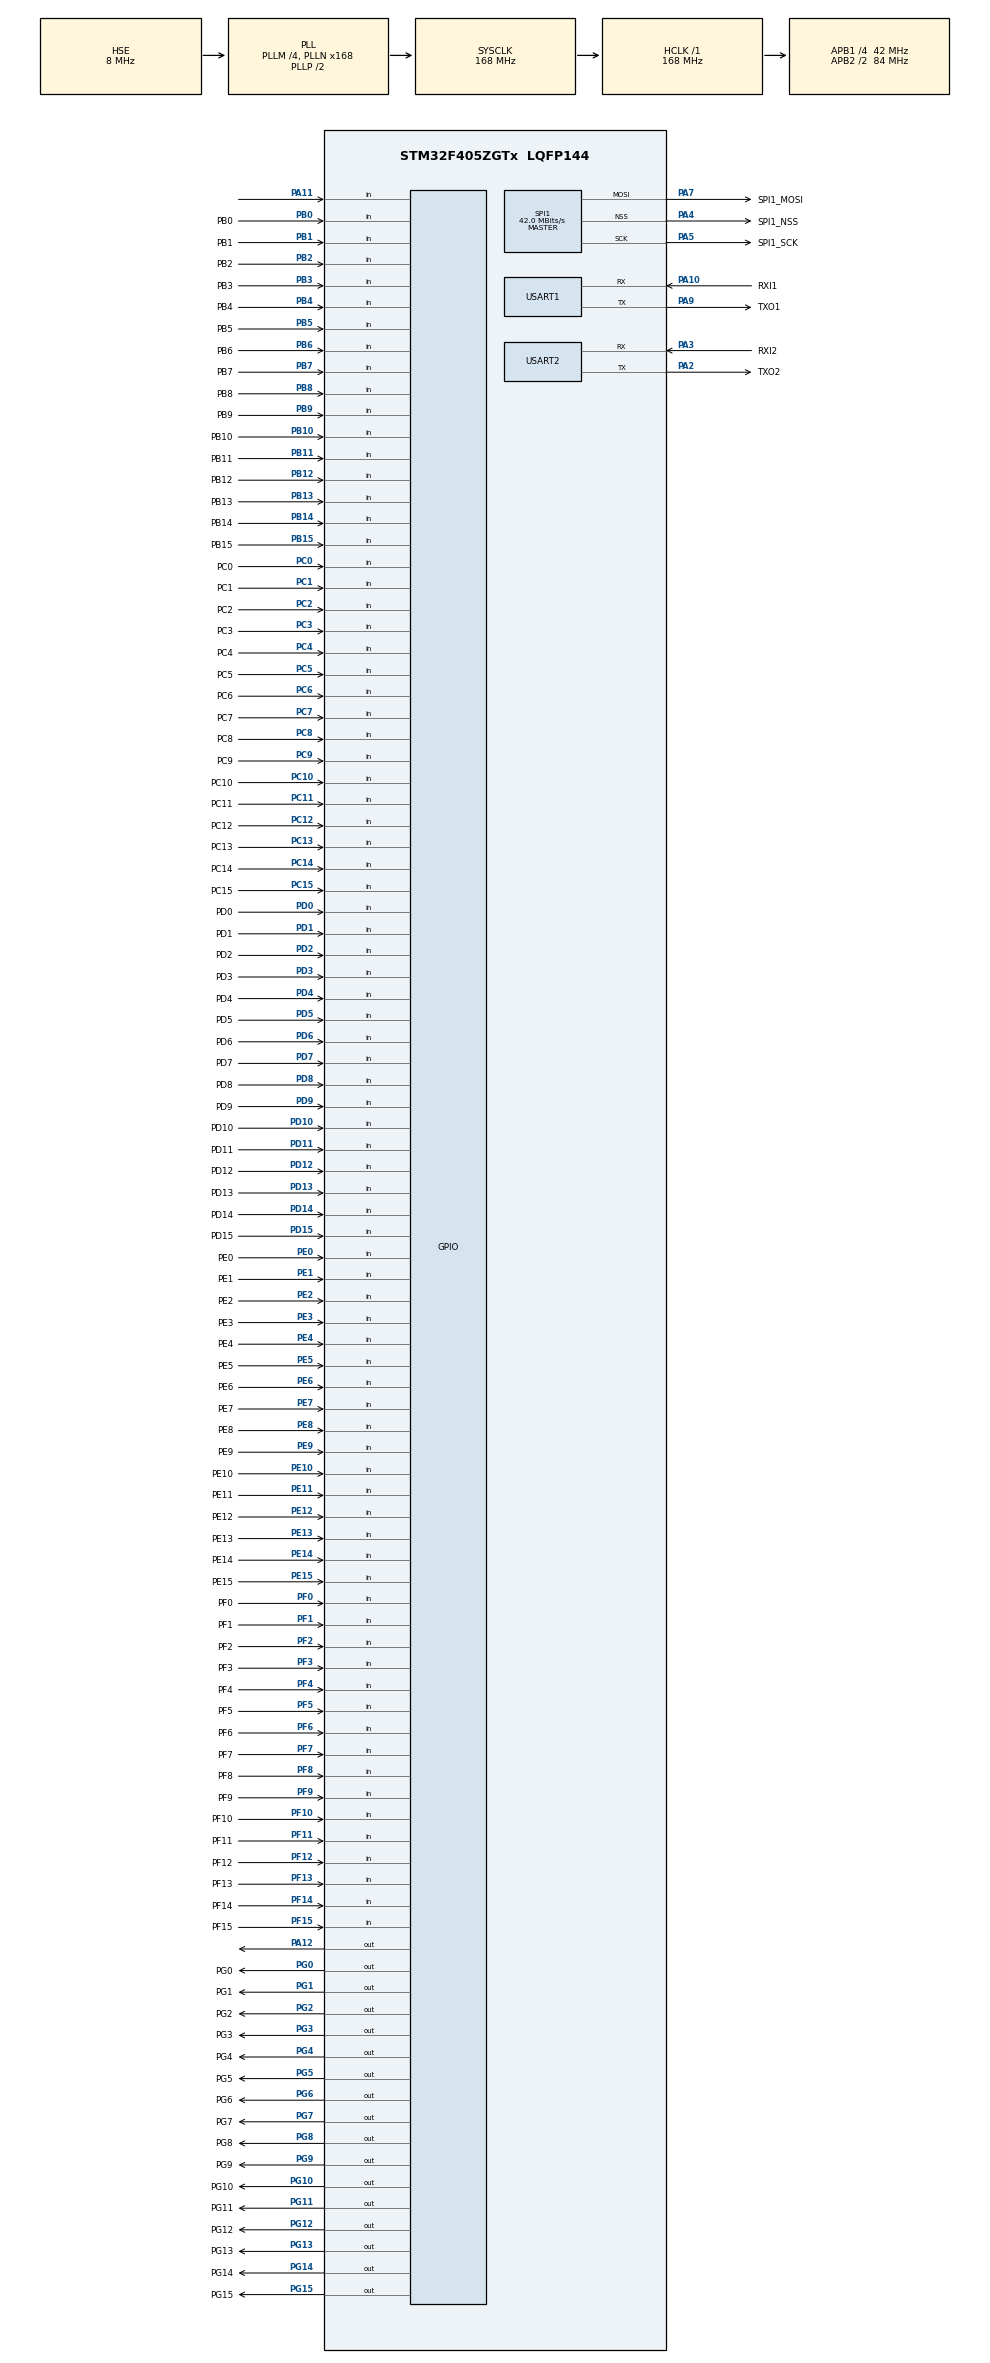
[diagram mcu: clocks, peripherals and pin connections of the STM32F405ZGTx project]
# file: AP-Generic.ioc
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Mcu.Family=STM32F4
Mcu.Name=STM32F405ZGTx
Mcu.Package=LQFP144
NVIC.PriorityGroup=NVIC_PRIORITYGROUP_4
NVIC.USART1_IRQn=true\:0\:0\:false\:false\:true\:true\:true\:true
PA10.GPIO_Label=RXI1
PA10.GPIO_PuPd=GPIO_PULLUP
PA10.Mode=Asynchronous
PA10.Signal=USART1_RX
PA11.GPIO_PuPd=GPIO_PULLUP
PA11.Signal=GPIO_Input
PA12.Signal=GPIO_Output
PA2.GPIO_Label=TXO2
PA2.Mode=Asynchronous
PA2.Signal=USART2_TX
PA3.GPIO_Label=RXI2
PA3.GPIO_PuPd=GPIO_PULLUP
PA3.Mode=Asynchronous
PA3.Signal=USART2_RX
PA4.GPIO_Label=SPI1_NSS
PA4.GPIO_PuPd=GPIO_PULLUP
PA4.Mode=NSS_Signal_Hard_Output
PA4.Signal=SPI1_NSS
PA5.GPIO_Label=SPI1_SCK
PA5.Mode=TX_Only_Simplex_Unidirect_Master
PA5.Signal=SPI1_SCK
PA6.GPIO_Label=SPI1_MIS0
PA6.GPIO_PuPd=GPIO_PULLDOWN
PA6.Signal=SPI1_MISO
PA7.GPIO_Label=SPI1_MOSI
PA7.Mode=TX_Only_Simplex_Unidirect_Master
PA7.Signal=SPI1_MOSI
PA9.GPIO_Label=TXO1
PA9.Mode=Asynchronous
PA9.Signal=USART1_TX
PB0.GPIO_Label=PB0
PB0.GPIO_PuPd=GPIO_PULLDOWN
PB0.Signal=GPIO_Input
PB1.GPIO_Label=PB1
PB1.GPIO_PuPd=GPIO_PULLDOWN
PB1.Signal=GPIO_Input
PB10.GPIO_Label=PB10
PB10.GPIO_PuPd=GPIO_PULLDOWN
PB10.Signal=GPIO_Input
PB11.GPIO_Label=PB11
PB11.GPIO_PuPd=GPIO_PULLDOWN
PB11.Signal=GPIO_Input
PB12.GPIO_Label=PB12
PB12.GPIO_PuPd=GPIO_PULLDOWN
PB12.Signal=GPIO_Input
PB13.GPIO_Label=PB13
PB13.GPIO_PuPd=GPIO_PULLDOWN
PB13.Signal=GPIO_Input
PB14.GPIO_Label=PB14
PB14.GPIO_PuPd=GPIO_PULLDOWN
PB14.Signal=GPIO_Input
PB15.GPIO_Label=PB15
PB15.GPIO_PuPd=GPIO_PULLDOWN
PB15.Signal=GPIO_Input
PB2.GPIO_Label=PB2
PB2.GPIO_PuPd=GPIO_PULLDOWN
PB2.Signal=GPIO_Input
PB3.GPIO_Label=PB3
PB3.GPIO_PuPd=GPIO_PULLDOWN
PB3.Signal=GPIO_Input
PB4.GPIO_Label=PB4
PB4.GPIO_PuPd=GPIO_PULLDOWN
PB4.Signal=GPIO_Input
PB5.GPIO_Label=PB5
PB5.GPIO_PuPd=GPIO_PULLDOWN
PB5.Signal=GPIO_Input
PB6.GPIO_Label=PB6
PB6.GPIO_PuPd=GPIO_PULLDOWN
PB6.Signal=GPIO_Input
PB7.GPIO_Label=PB7
PB7.GPIO_PuPd=GPIO_PULLDOWN
PB7.Signal=GPIO_Input
PB8.GPIO_Label=PB8
PB8.GPIO_PuPd=GPIO_PULLDOWN
PB8.Signal=GPIO_Input
PB9.GPIO_Label=PB9
PB9.GPIO_PuPd=GPIO_PULLDOWN
PB9.Signal=GPIO_Input
PC0.GPIO_Label=PC0
PC0.GPIO_PuPd=GPIO_PULLDOWN
PC0.Signal=GPIO_Input
PC1.GPIO_Label=PC1
PC1.GPIO_PuPd=GPIO_PULLDOWN
PC1.Signal=GPIO_Input
PC10.GPIO_Label=PC10
PC10.GPIO_PuPd=GPIO_PULLDOWN
PC10.Signal=GPIO_Input
PC11.GPIO_Label=PC11
PC11.GPIO_PuPd=GPIO_PULLDOWN
PC11.Signal=GPIO_Input
PC12.GPIO_Label=PC12
PC12.GPIO_PuPd=GPIO_PULLDOWN
PC12.Signal=GPIO_Input
PC13-ANTI_TAMP.GPIO_Label=PC13
PC13-ANTI_TAMP.GPIO_PuPd=GPIO_PULLDOWN
PC13-ANTI_TAMP.Signal=GPIO_Input
PC14-OSC32_IN.GPIO_Label=PC14
PC14-OSC32_IN.GPIO_PuPd=GPIO_PULLDOWN
PC14-OSC32_IN.Signal=GPIO_Input
PC15-OSC32_OUT.GPIO_Label=PC15
PC15-OSC32_OUT.GPIO_PuPd=GPIO_PULLDOWN
PC15-OSC32_OUT.Signal=GPIO_Input
PC2.GPIO_Label=PC2
PC2.GPIO_PuPd=GPIO_PULLDOWN
PC2.Signal=GPIO_Input
PC3.GPIO_Label=PC3
PC3.GPIO_PuPd=GPIO_PULLDOWN
PC3.Signal=GPIO_Input
PC4.GPIO_Label=PC4
PC4.GPIO_PuPd=GPIO_PULLDOWN
PC4.Signal=GPIO_Input
PC5.GPIO_Label=PC5
PC5.GPIO_PuPd=GPIO_PULLDOWN
PC5.Signal=GPIO_Input
PC6.GPIO_Label=PC6
PC6.GPIO_PuPd=GPIO_PULLDOWN
PC6.Signal=GPIO_Input
PC7.GPIO_Label=PC7
PC7.GPIO_PuPd=GPIO_PULLDOWN
PC7.Signal=GPIO_Input
PC8.GPIO_Label=PC8
PC8.GPIO_PuPd=GPIO_PULLDOWN
PC8.Signal=GPIO_Input
PC9.GPIO_Label=PC9
PC9.GPIO_PuPd=GPIO_PULLDOWN
PC9.Signal=GPIO_Input
PD0.GPIO_Label=PD0
PD0.GPIO_PuPd=GPIO_PULLDOWN
PD0.Signal=GPIO_Input
PD1.GPIO_Label=PD1
PD1.GPIO_PuPd=GPIO_PULLDOWN
PD1.Signal=GPIO_Input
PD10.GPIO_Label=PD10
PD10.GPIO_PuPd=GPIO_PULLDOWN
PD10.Signal=GPIO_Input
PD11.GPIO_Label=PD11
PD11.GPIO_PuPd=GPIO_PULLDOWN
PD11.Signal=GPIO_Input
PD12.GPIO_Label=PD12
PD12.GPIO_PuPd=GPIO_PULLDOWN
PD12.Signal=GPIO_Input
PD13.GPIO_Label=PD13
PD13.GPIO_PuPd=GPIO_PULLDOWN
PD13.Signal=GPIO_Input
PD14.GPIO_Label=PD14
PD14.GPIO_PuPd=GPIO_PULLDOWN
PD14.Signal=GPIO_Input
PD15.GPIO_Label=PD15
PD15.GPIO_PuPd=GPIO_PULLDOWN
PD15.Signal=GPIO_Input
PD2.GPIO_Label=PD2
PD2.GPIO_PuPd=GPIO_PULLDOWN
PD2.Signal=GPIO_Input
PD3.GPIO_Label=PD3
PD3.GPIO_PuPd=GPIO_PULLDOWN
PD3.Signal=GPIO_Input
PD4.GPIO_Label=PD4
PD4.GPIO_PuPd=GPIO_PULLDOWN
PD4.Signal=GPIO_Input
PD5.GPIO_Label=PD5
PD5.GPIO_PuPd=GPIO_PULLDOWN
PD5.Signal=GPIO_Input
PD6.GPIO_Label=PD6
PD6.GPIO_PuPd=GPIO_PULLDOWN
PD6.Signal=GPIO_Input
PD7.GPIO_Label=PD7
PD7.GPIO_PuPd=GPIO_PULLDOWN
PD7.Signal=GPIO_Input
PD8.GPIO_Label=PD8
PD8.GPIO_PuPd=GPIO_PULLDOWN
PD8.Signal=GPIO_Input
PD9.GPIO_Label=PD9
PD9.GPIO_PuPd=GPIO_PULLDOWN
PD9.Signal=GPIO_Input
PE0.GPIO_Label=PE0
PE0.GPIO_PuPd=GPIO_PULLDOWN
PE0.Signal=GPIO_Input
PE1.GPIO_Label=PE1
PE1.GPIO_PuPd=GPIO_PULLDOWN
PE1.Signal=GPIO_Input
PE10.GPIO_Label=PE10
PE10.GPIO_PuPd=GPIO_PULLDOWN
PE10.Signal=GPIO_Input
PE11.GPIO_Label=PE11
PE11.GPIO_PuPd=GPIO_PULLDOWN
PE11.Signal=GPIO_Input
PE12.GPIO_Label=PE12
PE12.GPIO_PuPd=GPIO_PULLDOWN
PE12.Signal=GPIO_Input
PE13.GPIO_Label=PE13
PE13.GPIO_PuPd=GPIO_PULLDOWN
PE13.Signal=GPIO_Input
PE14.GPIO_Label=PE14
PE14.GPIO_PuPd=GPIO_PULLDOWN
PE14.Signal=GPIO_Input
PE15.GPIO_Label=PE15
PE15.GPIO_PuPd=GPIO_PULLDOWN
PE15.Signal=GPIO_Input
PE2.GPIO_Label=PE2
PE2.GPIO_PuPd=GPIO_PULLDOWN
PE2.Signal=GPIO_Input
PE3.GPIO_Label=PE3
PE3.GPIO_PuPd=GPIO_PULLDOWN
PE3.Signal=GPIO_Input
PE4.GPIO_Label=PE4
PE4.GPIO_PuPd=GPIO_PULLDOWN
PE4.Signal=GPIO_Input
PE5.GPIO_Label=PE5
PE5.GPIO_PuPd=GPIO_PULLDOWN
PE5.Signal=GPIO_Input
PE6.GPIO_Label=PE6
PE6.GPIO_PuPd=GPIO_PULLDOWN
PE6.Signal=GPIO_Input
PE7.GPIO_Label=PE7
PE7.GPIO_PuPd=GPIO_PULLDOWN
PE7.Signal=GPIO_Input
PE8.GPIO_Label=PE8
PE8.GPIO_PuPd=GPIO_PULLDOWN
PE8.Signal=GPIO_Input
PE9.GPIO_Label=PE9
PE9.GPIO_PuPd=GPIO_PULLDOWN
PE9.Signal=GPIO_Input
PF0.GPIO_Label=PF0
PF0.GPIO_PuPd=GPIO_PULLDOWN
PF0.Signal=GPIO_Input
PF1.GPIO_Label=PF1
PF1.GPIO_PuPd=GPIO_PULLDOWN
PF1.Signal=GPIO_Input
PF10.GPIO_Label=PF10
PF10.GPIO_PuPd=GPIO_PULLDOWN
PF10.Signal=GPIO_Input
PF11.GPIO_Label=PF11
PF11.GPIO_PuPd=GPIO_PULLDOWN
PF11.Signal=GPIO_Input
PF12.GPIO_Label=PF12
PF12.GPIO_PuPd=GPIO_PULLDOWN
PF12.Signal=GPIO_Input
PF13.GPIO_Label=PF13
PF13.GPIO_PuPd=GPIO_PULLDOWN
PF13.Signal=GPIO_Input
PF14.GPIO_Label=PF14
PF14.GPIO_PuPd=GPIO_PULLDOWN
PF14.Signal=GPIO_Input
PF15.GPIO_Label=PF15
PF15.GPIO_PuPd=GPIO_PULLDOWN
PF15.Signal=GPIO_Input
PF2.GPIO_Label=PF2
PF2.GPIO_PuPd=GPIO_PULLDOWN
PF2.Signal=GPIO_Input
PF3.GPIO_Label=PF3
PF3.GPIO_PuPd=GPIO_PULLDOWN
PF3.Signal=GPIO_Input
PF4.GPIO_Label=PF4
PF4.GPIO_PuPd=GPIO_PULLDOWN
PF4.Signal=GPIO_Input
PF5.GPIO_Label=PF5
PF5.GPIO_PuPd=GPIO_PULLDOWN
PF5.Signal=GPIO_Input
PF6.GPIO_Label=PF6
PF6.GPIO_PuPd=GPIO_PULLDOWN
PF6.Signal=GPIO_Input
PF7.GPIO_Label=PF7
PF7.GPIO_PuPd=GPIO_PULLDOWN
PF7.Signal=GPIO_Input
PF8.GPIO_Label=PF8
PF8.GPIO_PuPd=GPIO_PULLDOWN
PF8.Signal=GPIO_Input
PF9.GPIO_Label=PF9
PF9.GPIO_PuPd=GPIO_PULLDOWN
PF9.Signal=GPIO_Input
PG0.GPIO_Label=PG0
PG0.Signal=GPIO_Output
PG1.GPIO_Label=PG1
PG1.Signal=GPIO_Output
PG10.GPIO_Label=PG10
PG10.Signal=GPIO_Output
PG11.GPIO_Label=PG11
PG11.Signal=GPIO_Output
PG12.GPIO_Label=PG12
PG12.Signal=GPIO_Output
PG13.GPIO_Label=PG13
PG13.Signal=GPIO_Output
PG14.GPIO_Label=PG14
PG14.Signal=GPIO_Output
PG15.GPIO_Label=PG15
PG15.Signal=GPIO_Output
PG2.GPIO_Label=PG2
PG2.Signal=GPIO_Output
PG3.GPIO_Label=PG3
PG3.Signal=GPIO_Output
PG4.GPIO_Label=PG4
PG4.Signal=GPIO_Output
PG5.GPIO_Label=PG5
PG5.Signal=GPIO_Output
PG6.GPIO_Label=PG6
PG6.Signal=GPIO_Output
PG7.GPIO_Label=PG7
PG7.Signal=GPIO_Output
PG8.GPIO_Label=PG8
PG8.Signal=GPIO_Output
PG9.GPIO_Label=PG9
PG9.Signal=GPIO_Output
PH0-OSC_IN.Mode=HSE-External-Oscillator
PH0-OSC_IN.Signal=RCC_OSC_IN
PH1-OSC_OUT.Mode=HSE-External-Oscillator
PH1-OSC_OUT.Signal=RCC_OSC_OUT
ProjectManager.HeapSize=0x200
ProjectManager.StackSize=0x400
ProjectManager.TargetToolchain=STM32CubeIDE
RCC.48MHZClocksFreq_Value=84000000
RCC.AHBFreq_Value=168000000
RCC.APB1CLKDivider=RCC_HCLK_DIV4
RCC.APB1Freq_Value=42000000
RCC.APB1TimFreq_Value=84000000
RCC.APB2CLKDivider=RCC_HCLK_DIV2
RCC.APB2Freq_Value=84000000
RCC.APB2TimFreq_Value=168000000
RCC.CortexFreq_Value=168000000
RCC.HCLKFreq_Value=168000000
RCC.HSE_VALUE=8000000
RCC.HSI_VALUE=16000000
RCC.LSE_VALUE=32768
RCC.PLLM=4
RCC.PLLN=168
RCC.PLLSourceVirtual=RCC_PLLSOURCE_HSE
RCC.SYSCLKFreq_VALUE=168000000
RCC.SYSCLKSource=RCC_SYSCLKSOURCE_PLLCLK
RCC.VCOOutputFreq_Value=336000000
SPI1.BaudRatePrescaler=SPI_BAUDRATEPRESCALER_2
SPI1.CalculateBaudRate=42.0 MBits/s
SPI1.Direction=SPI_DIRECTION_2LINES
SPI1.Mode=SPI_MODE_MASTER
SPI1.VirtualNSS=VM_NSSHARD
SPI1.VirtualType=VM_MASTER
USART1.VirtualMode=VM_ASYNC
USART2.VirtualMode=VM_ASYNC
board=custom

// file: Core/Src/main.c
/* USER CODE BEGIN Header */
/**
  ******************************************************************************
  * @file           : main.c
  * @brief          : Main program body
  ******************************************************************************
  * @attention
  *
  * Copyright (c) 2025 STMicroelectronics.
  * All rights reserved.
  *
  * This software is licensed under terms that can be found in the LICENSE file
  * in the root directory of this software component.
  * If no LICENSE file comes with this software, it is provided AS-IS.
  *
  ******************************************************************************
  */
/* USER CODE END Header */
#include "main.h"

/* USER CODE BEGIN Includes */
#include "UserApp.h"
/* USER CODE END Includes */

SPI_HandleTypeDef hspi1;

UART_HandleTypeDef huart1;
UART_HandleTypeDef huart2;

void SystemClock_Config(void);
static void MX_GPIO_Init(void);
static void MX_SPI1_Init(void);
static void MX_USART1_UART_Init(void);
static void MX_USART2_UART_Init(void);

int main(void)
{

  /* MCU Configuration--------------------------------------------------------*/

  /* Reset of all peripherals, Initializes the Flash interface and the Systick. */
  HAL_Init();

  /* Configure the system clock */
  SystemClock_Config();

  /* Initialize all configured peripherals */
  MX_GPIO_Init();
  MX_SPI1_Init();
  MX_USART1_UART_Init();
  MX_USART2_UART_Init();
  /* USER CODE BEGIN 2 */
  setup();
  /* USER CODE END 2 */

  /* Infinite loop */
  while (1)
  {

    /* USER CODE BEGIN 3 */
	loop();
  }
  /* USER CODE END 3 */
}

void SystemClock_Config(void)
{
  RCC_OscInitTypeDef RCC_OscInitStruct = {0};
  RCC_ClkInitTypeDef RCC_ClkInitStruct = {0};

  /** Configure the main internal regulator output voltage
  */
  __HAL_RCC_PWR_CLK_ENABLE();
  __HAL_PWR_VOLTAGESCALING_CONFIG(PWR_REGULATOR_VOLTAGE_SCALE1);

  /** Initializes the RCC Oscillators according to the specified parameters
  * in the RCC_OscInitTypeDef structure.
  */
  RCC_OscInitStruct.OscillatorType = RCC_OSCILLATORTYPE_HSE;
  RCC_OscInitStruct.HSEState = RCC_HSE_ON;
  RCC_OscInitStruct.PLL.PLLState = RCC_PLL_ON;
  RCC_OscInitStruct.PLL.PLLSource = RCC_PLLSOURCE_HSE;
  RCC_OscInitStruct.PLL.PLLM = 4;
  RCC_OscInitStruct.PLL.PLLN = 168;
  RCC_OscInitStruct.PLL.PLLP = RCC_PLLP_DIV2;
  RCC_OscInitStruct.PLL.PLLQ = 4;
  if (HAL_RCC_OscConfig(&RCC_OscInitStruct) != HAL_OK)
  {
    Error_Handler();
  }

  /** Initializes the CPU, AHB and APB buses clocks
  */
  RCC_ClkInitStruct.ClockType = RCC_CLOCKTYPE_HCLK|RCC_CLOCKTYPE_SYSCLK
                              |RCC_CLOCKTYPE_PCLK1|RCC_CLOCKTYPE_PCLK2;
  RCC_ClkInitStruct.SYSCLKSource = RCC_SYSCLKSOURCE_PLLCLK;
  RCC_ClkInitStruct.AHBCLKDivider = RCC_SYSCLK_DIV1;
  RCC_ClkInitStruct.APB1CLKDivider = RCC_HCLK_DIV4;
  RCC_ClkInitStruct.APB2CLKDivider = RCC_HCLK_DIV2;

  if (HAL_RCC_ClockConfig(&RCC_ClkInitStruct, FLASH_LATENCY_5) != HAL_OK)
  {
    Error_Handler();
  }
}

static void MX_SPI1_Init(void)
{

  /* SPI1 parameter configuration*/
  hspi1.Instance = SPI1;
  hspi1.Init.Mode = SPI_MODE_MASTER;
  hspi1.Init.Direction = SPI_DIRECTION_2LINES;
  hspi1.Init.DataSize = SPI_DATASIZE_8BIT;
  hspi1.Init.CLKPolarity = SPI_POLARITY_LOW;
  hspi1.Init.CLKPhase = SPI_PHASE_1EDGE;
  hspi1.Init.NSS = SPI_NSS_HARD_OUTPUT;
  hspi1.Init.BaudRatePrescaler = SPI_BAUDRATEPRESCALER_2;
  hspi1.Init.FirstBit = SPI_FIRSTBIT_MSB;
  hspi1.Init.TIMode = SPI_TIMODE_DISABLE;
  hspi1.Init.CRCCalculation = SPI_CRCCALCULATION_DISABLE;
  hspi1.Init.CRCPolynomial = 10;
  if (HAL_SPI_Init(&hspi1) != HAL_OK)
  {
    Error_Handler();
  }

}

static void MX_USART1_UART_Init(void)
{

  huart1.Instance = USART1;
  huart1.Init.BaudRate = 115200;
  huart1.Init.WordLength = UART_WORDLENGTH_8B;
  huart1.Init.StopBits = UART_STOPBITS_1;
  huart1.Init.Parity = UART_PARITY_NONE;
  huart1.Init.Mode = UART_MODE_TX_RX;
  huart1.Init.HwFlowCtl = UART_HWCONTROL_NONE;
  huart1.Init.OverSampling = UART_OVERSAMPLING_16;
  if (HAL_UART_Init(&huart1) != HAL_OK)
  {
    Error_Handler();
  }

}

static void MX_USART2_UART_Init(void)
{

  huart2.Instance = USART2;
  huart2.Init.BaudRate = 115200;
  huart2.Init.WordLength = UART_WORDLENGTH_8B;
  huart2.Init.StopBits = UART_STOPBITS_1;
  huart2.Init.Parity = UART_PARITY_NONE;
  huart2.Init.Mode = UART_MODE_TX_RX;
  huart2.Init.HwFlowCtl = UART_HWCONTROL_NONE;
  huart2.Init.OverSampling = UART_OVERSAMPLING_16;
  if (HAL_UART_Init(&huart2) != HAL_OK)
  {
    Error_Handler();
  }

}

static void MX_GPIO_Init(void)
{
  GPIO_InitTypeDef GPIO_InitStruct = {0};

  /* GPIO Ports Clock Enable */
  __HAL_RCC_GPIOE_CLK_ENABLE();
  __HAL_RCC_GPIOC_CLK_ENABLE();
  __HAL_RCC_GPIOF_CLK_ENABLE();
  __HAL_RCC_GPIOH_CLK_ENABLE();
  __HAL_RCC_GPIOA_CLK_ENABLE();
  __HAL_RCC_GPIOB_CLK_ENABLE();
  __HAL_RCC_GPIOG_CLK_ENABLE();
  __HAL_RCC_GPIOD_CLK_ENABLE();

  /*Configure GPIO pin Output Level */
  HAL_GPIO_WritePin(GPIOG, PG0_Pin|PG1_Pin|PG2_Pin|PG3_Pin
                          |PG4_Pin|PG5_Pin|PG6_Pin|PG7_Pin
                          |PG8_Pin|PG9_Pin|PG10_Pin|PG11_Pin
                          |PG12_Pin|PG13_Pin|PG14_Pin|PG15_Pin, GPIO_PIN_RESET);

  /*Configure GPIO pin Output Level */
  HAL_GPIO_WritePin(GPIOA, GPIO_PIN_12, GPIO_PIN_RESET);

  /*Configure GPIO pins : PE2_Pin PE3_Pin PE4_Pin PE5_Pin
                           PE6_Pin PE7_Pin PE8_Pin PE9_Pin
                           PE10_Pin PE11_Pin PE12_Pin PE13_Pin
                           PE14_Pin PE15_Pin PE0_Pin PE1_Pin */
  GPIO_InitStruct.Pin = PE2_Pin|PE3_Pin|PE4_Pin|PE5_Pin
                          |PE6_Pin|PE7_Pin|PE8_Pin|PE9_Pin
                          |PE10_Pin|PE11_Pin|PE12_Pin|PE13_Pin
                          |PE14_Pin|PE15_Pin|PE0_Pin|PE1_Pin;
  GPIO_InitStruct.Mode = GPIO_MODE_INPUT;
  GPIO_InitStruct.Pull = GPIO_PULLDOWN;
  HAL_GPIO_Init(GPIOE, &GPIO_InitStruct);

  /*Configure GPIO pins : PC13_Pin PC14_Pin PC15_Pin PC0_Pin
                           PC1_Pin PC2_Pin PC3_Pin PC4_Pin
                           PC5_Pin PC6_Pin PC7_Pin PC8_Pin
                           PC9_Pin PC10_Pin PC11_Pin PC12_Pin */
  GPIO_InitStruct.Pin = PC13_Pin|PC14_Pin|PC15_Pin|PC0_Pin
                          |PC1_Pin|PC2_Pin|PC3_Pin|PC4_Pin
                          |PC5_Pin|PC6_Pin|PC7_Pin|PC8_Pin
                          |PC9_Pin|PC10_Pin|PC11_Pin|PC12_Pin;
  GPIO_InitStruct.Mode = GPIO_MODE_INPUT;
  GPIO_InitStruct.Pull = GPIO_PULLDOWN;
  HAL_GPIO_Init(GPIOC, &GPIO_InitStruct);

  /*Configure GPIO pins : PF0_Pin PF1_Pin PF2_Pin PF3_Pin
                           PF4_Pin PF5_Pin PF6_Pin PF7_Pin
                           PF8_Pin PF9_Pin PF10_Pin PF11_Pin
                           PF12_Pin PF13_Pin PF14_Pin PF15_Pin */
  GPIO_InitStruct.Pin = PF0_Pin|PF1_Pin|PF2_Pin|PF3_Pin
                          |PF4_Pin|PF5_Pin|PF6_Pin|PF7_Pin
                          |PF8_Pin|PF9_Pin|PF10_Pin|PF11_Pin
                          |PF12_Pin|PF13_Pin|PF14_Pin|PF15_Pin;
  GPIO_InitStruct.Mode = GPIO_MODE_INPUT;
  GPIO_InitStruct.Pull = GPIO_PULLDOWN;
  HAL_GPIO_Init(GPIOF, &GPIO_InitStruct);

  /*Configure GPIO pins : PB0_Pin PB1_Pin PB2_Pin PB10_Pin
                           PB11_Pin PB12_Pin PB13_Pin PB14_Pin
                           PB15_Pin PB3_Pin PB4_Pin PB5_Pin
                           PB6_Pin PB7_Pin PB8_Pin PB9_Pin */
  GPIO_InitStruct.Pin = PB0_Pin|PB1_Pin|PB2_Pin|PB10_Pin
                          |PB11_Pin|PB12_Pin|PB13_Pin|PB14_Pin
                          |PB15_Pin|PB3_Pin|PB4_Pin|PB5_Pin
                          |PB6_Pin|PB7_Pin|PB8_Pin|PB9_Pin;
  GPIO_InitStruct.Mode = GPIO_MODE_INPUT;
  GPIO_InitStruct.Pull = GPIO_PULLDOWN;
  HAL_GPIO_Init(GPIOB, &GPIO_InitStruct);

  /*Configure GPIO pins : PG0_Pin PG1_Pin PG2_Pin PG3_Pin
                           PG4_Pin PG5_Pin PG6_Pin PG7_Pin
                           PG8_Pin PG9_Pin PG10_Pin PG11_Pin
                           PG12_Pin PG13_Pin PG14_Pin PG15_Pin */
  GPIO_InitStruct.Pin = PG0_Pin|PG1_Pin|PG2_Pin|PG3_Pin
                          |PG4_Pin|PG5_Pin|PG6_Pin|PG7_Pin
                          |PG8_Pin|PG9_Pin|PG10_Pin|PG11_Pin
                          |PG12_Pin|PG13_Pin|PG14_Pin|PG15_Pin;
  GPIO_InitStruct.Mode = GPIO_MODE_OUTPUT_PP;
  GPIO_InitStruct.Pull = GPIO_NOPULL;
  GPIO_InitStruct.Speed = GPIO_SPEED_FREQ_LOW;
  HAL_GPIO_Init(GPIOG, &GPIO_InitStruct);

  /*Configure GPIO pins : PD8_Pin PD9_Pin PD10_Pin PD11_Pin
                           PD12_Pin PD13_Pin PD14_Pin PD15_Pin
                           PD0_Pin PD1_Pin PD2_Pin PD3_Pin
                           PD4_Pin PD5_Pin PD6_Pin PD7_Pin */
  GPIO_InitStruct.Pin = PD8_Pin|PD9_Pin|PD10_Pin|PD11_Pin
                          |PD12_Pin|PD13_Pin|PD14_Pin|PD15_Pin
                          |PD0_Pin|PD1_Pin|PD2_Pin|PD3_Pin
                          |PD4_Pin|PD5_Pin|PD6_Pin|PD7_Pin;
  GPIO_InitStruct.Mode = GPIO_MODE_INPUT;
  GPIO_InitStruct.Pull = GPIO_PULLDOWN;
  HAL_GPIO_Init(GPIOD, &GPIO_InitStruct);

  /*Configure GPIO pin : PA11 */
  GPIO_InitStruct.Pin = GPIO_PIN_11;
  GPIO_InitStruct.Mode = GPIO_MODE_INPUT;
  GPIO_InitStruct.Pull = GPIO_PULLUP;
  HAL_GPIO_Init(GPIOA, &GPIO_InitStruct);

  /*Configure GPIO pin : PA12 */
  GPIO_InitStruct.Pin = GPIO_PIN_12;
  GPIO_InitStruct.Mode = GPIO_MODE_OUTPUT_PP;
  GPIO_InitStruct.Pull = GPIO_NOPULL;
  GPIO_InitStruct.Speed = GPIO_SPEED_FREQ_LOW;
  HAL_GPIO_Init(GPIOA, &GPIO_InitStruct);

}

void Error_Handler(void)
{
  __disable_irq();
  while (1)
  {
  }
}
